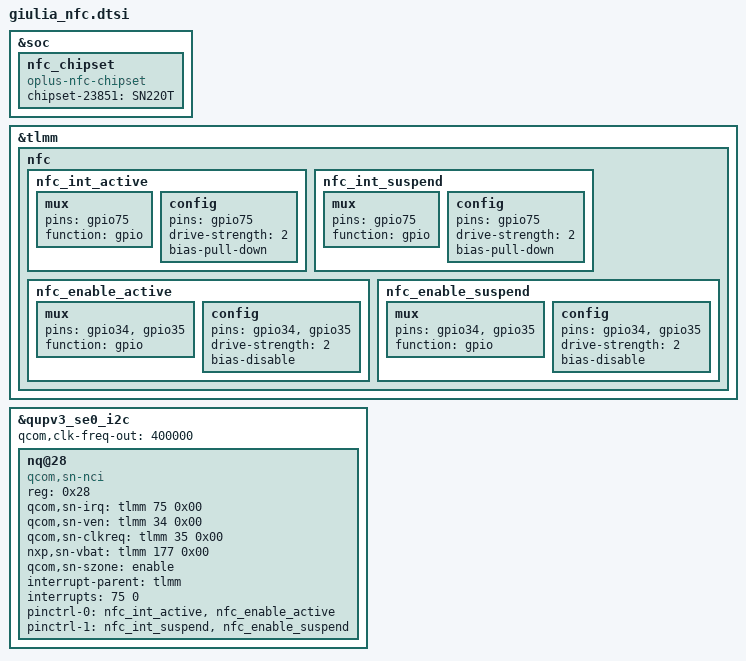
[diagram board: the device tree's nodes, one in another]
#include <dt-bindings/clock/qcom,rpmh.h>

&soc {
    //add for nfc_chipset
    nfc_chipset {
        compatible = "oplus-nfc-chipset";
        chipset-23851 = "SN220T";
    };
};
&tlmm {
	nfc {
		nfc_int_active: nfc_int_active {
			/* active state */
			mux {
				/* NFC Read Interrupt */
				pins = "gpio75";
				function = "gpio";
			};

			config {
				pins = "gpio75";
				drive-strength = <2>; /* 2 MA */
				bias-pull-down;
			};
		};

		nfc_int_suspend: nfc_int_suspend {
			/* sleep state */
			mux {
				/* NFC Read Interrupt */
				pins = "gpio75";
				function = "gpio";
			};

			config {
				pins = "gpio75";
				drive-strength = <2>; /* 2 MA */
				bias-pull-down;
			};
		};

		nfc_enable_active: nfc_enable_active {
			mux {
				/* Enable, and Clock request gpios */
				pins = "gpio34", "gpio35";
				function = "gpio";
			};

			config {
				pins = "gpio34", "gpio35";
				drive-strength = <2>; /* 2 MA */
				bias-disable;
			};
		};

		nfc_enable_suspend: nfc_enable_suspend {
			mux {
				pins = "gpio34", "gpio35";
				function = "gpio";
			};

			config {
				pins = "gpio34", "gpio35";
				drive-strength = <2>; /* 2 MA */
				bias-disable;
			};
		};
	}; //nfc
}; //tlmm
&qupv3_se0_i2c {
	status = "ok";
	qcom,clk-freq-out = <400000>;
	#address-cells = <1>;
	#size-cells = <0>;
	nq@28 {
		compatible = "qcom,sn-nci";
		reg = <0x28>;
		qcom,sn-irq = <&tlmm 75 0x00>;
		qcom,sn-ven = <&tlmm 34 0x00>;
		qcom,sn-clkreq = <&tlmm 35 0x00>;
		nxp,sn-vbat = <&tlmm 177 0x00>;
		qcom,sn-szone = "enable";
		interrupt-parent = <&tlmm>;
		interrupts = <75 0>;
		interrupt-names = "nfc_irq";
		pinctrl-names = "nfc_active", "nfc_suspend";
		pinctrl-0 = <&nfc_int_active &nfc_enable_active>;
		pinctrl-1 = <&nfc_int_suspend &nfc_enable_suspend>;
	};
};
